AUTOSAR XML (schema 4-2-2)
package /STELLANTIS/EPT/ASWCs
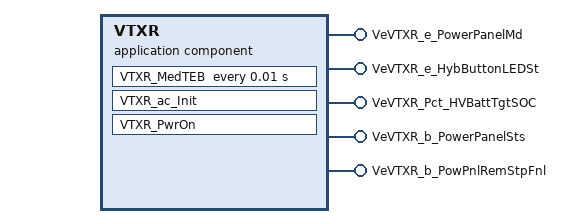
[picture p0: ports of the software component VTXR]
  application sw component type VTXR
    5 x provide port:
      VeVTXR_e_PowerPanelMd: nonqueued-sender-com-spec{data-element=Value, init-value=CeVTXR_e_DefaultMd}, provided-interface=VeVTXR_e_PowerPanelMd
      VeVTXR_e_HybButtonLEDSt: nonqueued-sender-com-spec{data-element=Value, init-value=CeAECR_e_LEDOff}, provided-interface=VeVTXR_e_HybButtonLEDSt
      VeVTXR_Pct_HVBattTgtSOC: nonqueued-sender-com-spec{data-element=Value, init-value=0}, provided-interface=VeVTXR_Pct_HVBattTgtSOC
      VeVTXR_b_PowerPanelSts: nonqueued-sender-com-spec{data-element=Value, init-value=0}, provided-interface=VeVTXR_b_PowerPanelSts
      VeVTXR_b_PowPnlRemStpFnl: nonqueued-sender-com-spec{data-element=Value, init-value=0}, provided-interface=VeVTXR_b_PowPnlRemStpFnl
    behavior IB_VTXR: data-type-mapping=msADTtoIDTMapping, handle-termination-and-restart=NO-SUPPORT, included-data-type-set=data-type=TeVTXR_e_STMTrigger
      timing event Event_MedTEB: start-on-event=VTXR_MedTEB, period=0.01
      init event Event_VTXR_ac_Init: start-on-event=VTXR_ac_Init
      init event Event_PwrOn: start-on-event=VTXR_PwrOn
      runnable VTXR_ac_Init
        data-send-points:
          access OUT_VeVTXR_e_PowerPanelMd_Value: accessed-variable=VeVTXR_e_PowerPanelMd.Value
          access OUT_VeVTXR_e_HybButtonLEDSt_Value: accessed-variable=VeVTXR_e_HybButtonLEDSt.Value
      runnable VTXR_MedTEB
        data-send-points:
          5 x access:
            OUT_VeVTXR_e_PowerPanelMd_Value: accessed-variable=VeVTXR_e_PowerPanelMd.Value
            OUT_VeVTXR_e_HybButtonLEDSt_Value: accessed-variable=VeVTXR_e_HybButtonLEDSt.Value
            OUT_VeVTXR_Pct_HVBattTgtSOC_Value: accessed-variable=VeVTXR_Pct_HVBattTgtSOC.Value
            OUT_VeVTXR_b_PowerPanelSts_Value: accessed-variable=VeVTXR_b_PowerPanelSts.Value
            OUT_VeVTXR_b_PowPnlRemStpFnl_Value: accessed-variable=VeVTXR_b_PowPnlRemStpFnl.Value
      runnable VTXR_PwrOn
        data-send-points:
          5 x access:
            OUT_VeVTXR_e_PowerPanelMd_Value: accessed-variable=VeVTXR_e_PowerPanelMd.Value
            OUT_VeVTXR_e_HybButtonLEDSt_Value: accessed-variable=VeVTXR_e_HybButtonLEDSt.Value
            OUT_VeVTXR_Pct_HVBattTgtSOC_Value: accessed-variable=VeVTXR_Pct_HVBattTgtSOC.Value
            OUT_VeVTXR_b_PowerPanelSts_Value: accessed-variable=VeVTXR_b_PowerPanelSts.Value
            OUT_VeVTXR_b_PowPnlRemStpFnl_Value: accessed-variable=VeVTXR_b_PowPnlRemStpFnl.Value
      4 x variation point proxy, all with category=CONDITION, condition-access=0:
        Variant_VTXR_EnblMinSOCInpt
        Variant_VTXR_HMIIntrfce
        Variant_VTXR_NoHMIIntrfce
        Variant_VTXR_PowPanelEqupd
